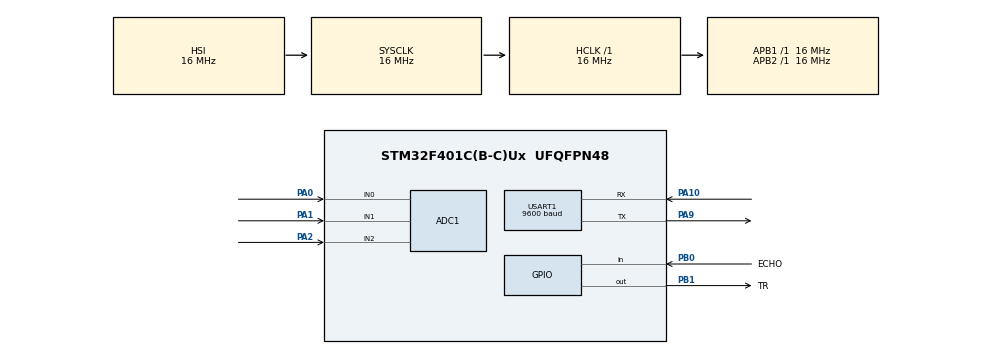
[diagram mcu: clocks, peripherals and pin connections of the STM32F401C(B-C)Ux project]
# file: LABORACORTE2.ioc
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ADC1.Channel-0\#ChannelRegularConversion=ADC_CHANNEL_0
ADC1.Channel-1\#ChannelRegularConversion=ADC_CHANNEL_1
ADC1.Channel-2\#ChannelRegularConversion=ADC_CHANNEL_2
ADC1.NbrOfConversion=3
ADC1.NbrOfConversionFlag=1
ADC1.Rank-0\#ChannelRegularConversion=1
ADC1.Rank-1\#ChannelRegularConversion=2
ADC1.Rank-2\#ChannelRegularConversion=3
ADC1.SamplingTime-0\#ChannelRegularConversion=ADC_SAMPLETIME_84CYCLES
ADC1.SamplingTime-1\#ChannelRegularConversion=ADC_SAMPLETIME_84CYCLES
ADC1.SamplingTime-2\#ChannelRegularConversion=ADC_SAMPLETIME_84CYCLES
ADC1.master=1
Mcu.Family=STM32F4
Mcu.Name=STM32F401C(B-C)Ux
Mcu.Package=UFQFPN48
NVIC.PriorityGroup=NVIC_PRIORITYGROUP_4
PA0-WKUP.Signal=ADCx_IN0
PA1.Signal=ADCx_IN1
PA10.Mode=Asynchronous
PA10.Signal=USART1_RX
PA2.Signal=ADCx_IN2
PA9.Mode=Asynchronous
PA9.Signal=USART1_TX
PB0.GPIO_Label=ECHO
PB0.Signal=GPIO_Input
PB1.GPIO_Label=TR
PB1.Signal=GPIO_Output
ProjectManager.HeapSize=0x200
ProjectManager.StackSize=0x400
ProjectManager.TargetToolchain=CMake
RCC.AHBFreq_Value=16000000
RCC.APB1Freq_Value=16000000
RCC.APB2Freq_Value=16000000
RCC.CortexFreq_Value=16000000
RCC.HSE_VALUE=25000000
RCC.HSI_VALUE=16000000
RCC.LSE_VALUE=32768
RCC.SYSCLKFreq_VALUE=16000000
RCC.VCOOutputFreq_Value=192000000
SH.ADCx_IN0.0=ADC1_IN0,IN0
SH.ADCx_IN1.0=ADC1_IN1,IN1
SH.ADCx_IN2.0=ADC1_IN2,IN2
USART1.BaudRate=9600
USART1.VirtualMode=VM_ASYNC
board=custom

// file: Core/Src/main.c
/* USER CODE BEGIN Header */
/**
  ******************************************************************************
  * @file           : main.c
  * @brief          : Main program body
  ******************************************************************************
  * @attention
  *
  * Copyright (c) 2026 STMicroelectronics.
  * All rights reserved.
  *
  * This software is licensed under terms that can be found in the LICENSE file
  * in the root directory of this software component.
  * If no LICENSE file comes with this software, it is provided AS-IS.
  *
  ******************************************************************************
  */
/* USER CODE END Header */
#include "main.h"

/* USER CODE BEGIN Includes */
#include "stdio.h"
#include "string.h"
#include "stdlib.h"
#include "math.h"
#include "uart.h"
#include "adc_x.h"
#include "SFR04.h"
/* USER CODE END Includes */

ADC_HandleTypeDef hadc1;

UART_HandleTypeDef huart1;

/* USER CODE BEGIN PV */
uint16_t valoradc;
char buffer[100];
float voltaje;
float bateria;
float distancia;

/* USER CODE END PV */

void SystemClock_Config(void);
static void MX_GPIO_Init(void);
static void MX_ADC1_Init(void);
static void MX_USART1_UART_Init(void);

int main(void)
{

  /* MCU Configuration--------------------------------------------------------*/

  /* Reset of all peripherals, Initializes the Flash interface and the Systick. */
  HAL_Init();

  /* Configure the system clock */
  SystemClock_Config();

  /* Initialize all configured peripherals */
  MX_GPIO_Init();
  MX_ADC1_Init();
  MX_USART1_UART_Init();

  /* Infinite loop */
  while (1)
  {
    ADC_Read_All(&hadc1, adc1_canales, adc1_codigo);
    voltaje = (float)adc1_codigo[0] * 3.3 / 4095.0;
    sprintf(buffer, "voltaje pot= %.2f V\r\n", voltaje);
    uartx_write_text(&huart1, buffer);
    sprintf(buffer, ">voltaje POT: %.2f \n", voltaje);
    uartx_write_text(&huart1, buffer);
    bateria = (float)adc1_codigo[1] * 3.3 / 4095.0;
    bateria = bateria * 4.9;
    sprintf(buffer, "fuente = %.2f V\r\n", bateria);
    uartx_write_text(&huart1, buffer);
    sprintf(buffer, ">fuente: %.2f \n", bateria);
    uartx_write_text(&huart1, buffer);
    distancia = SFR04_READ(ECHO_GPIO_Port, ECHO_Pin, 60);
    sprintf(buffer, "distancia= %.2f cm\r\n", distancia);
    uartx_write_text(&huart1, buffer);
    sprintf(buffer, ">distancia: %.2f \n", distancia);
    uartx_write_text(&huart1, buffer);
    HAL_Delay(500);
  }
}

void SystemClock_Config(void)
{
  RCC_OscInitTypeDef RCC_OscInitStruct = {0};
  RCC_ClkInitTypeDef RCC_ClkInitStruct = {0};

  /** Configure the main internal regulator output voltage
  */
  __HAL_RCC_PWR_CLK_ENABLE();
  __HAL_PWR_VOLTAGESCALING_CONFIG(PWR_REGULATOR_VOLTAGE_SCALE2);

  /** Initializes the RCC Oscillators according to the specified parameters
  * in the RCC_OscInitTypeDef structure.
  */
  RCC_OscInitStruct.OscillatorType = RCC_OSCILLATORTYPE_HSI;
  RCC_OscInitStruct.HSIState = RCC_HSI_ON;
  RCC_OscInitStruct.HSICalibrationValue = RCC_HSICALIBRATION_DEFAULT;
  RCC_OscInitStruct.PLL.PLLState = RCC_PLL_NONE;
  if (HAL_RCC_OscConfig(&RCC_OscInitStruct) != HAL_OK)
  {
    Error_Handler();
  }

  /** Initializes the CPU, AHB and APB buses clocks
  */
  RCC_ClkInitStruct.ClockType = RCC_CLOCKTYPE_HCLK|RCC_CLOCKTYPE_SYSCLK
                              |RCC_CLOCKTYPE_PCLK1|RCC_CLOCKTYPE_PCLK2;
  RCC_ClkInitStruct.SYSCLKSource = RCC_SYSCLKSOURCE_HSI;
  RCC_ClkInitStruct.AHBCLKDivider = RCC_SYSCLK_DIV1;
  RCC_ClkInitStruct.APB1CLKDivider = RCC_HCLK_DIV1;
  RCC_ClkInitStruct.APB2CLKDivider = RCC_HCLK_DIV1;

  if (HAL_RCC_ClockConfig(&RCC_ClkInitStruct, FLASH_LATENCY_0) != HAL_OK)
  {
    Error_Handler();
  }
}

static void MX_ADC1_Init(void)
{

  ADC_ChannelConfTypeDef sConfig = {0};

  /** Configure the global features of the ADC (Clock, Resolution, Data Alignment and number of conversion)
  */
  hadc1.Instance = ADC1;
  hadc1.Init.ClockPrescaler = ADC_CLOCK_SYNC_PCLK_DIV2;
  hadc1.Init.Resolution = ADC_RESOLUTION_12B;
  hadc1.Init.ScanConvMode = ENABLE;
  hadc1.Init.ContinuousConvMode = DISABLE;
  hadc1.Init.DiscontinuousConvMode = DISABLE;
  hadc1.Init.ExternalTrigConvEdge = ADC_EXTERNALTRIGCONVEDGE_NONE;
  hadc1.Init.ExternalTrigConv = ADC_SOFTWARE_START;
  hadc1.Init.DataAlign = ADC_DATAALIGN_RIGHT;
  hadc1.Init.NbrOfConversion = 3;
  hadc1.Init.DMAContinuousRequests = DISABLE;
  hadc1.Init.EOCSelection = ADC_EOC_SINGLE_CONV;
  if (HAL_ADC_Init(&hadc1) != HAL_OK)
  {
    Error_Handler();
  }

  /** Configure for the selected ADC regular channel its corresponding rank in the sequencer and its sample time.
  */
  sConfig.Channel = ADC_CHANNEL_0;
  sConfig.Rank = 1;
  sConfig.SamplingTime = ADC_SAMPLETIME_84CYCLES;
  if (HAL_ADC_ConfigChannel(&hadc1, &sConfig) != HAL_OK)
  {
    Error_Handler();
  }

  /** Configure for the selected ADC regular channel its corresponding rank in the sequencer and its sample time.
  */
  sConfig.Channel = ADC_CHANNEL_1;
  sConfig.Rank = 2;
  if (HAL_ADC_ConfigChannel(&hadc1, &sConfig) != HAL_OK)
  {
    Error_Handler();
  }

  /** Configure for the selected ADC regular channel its corresponding rank in the sequencer and its sample time.
  */
  sConfig.Channel = ADC_CHANNEL_2;
  sConfig.Rank = 3;
  if (HAL_ADC_ConfigChannel(&hadc1, &sConfig) != HAL_OK)
  {
    Error_Handler();
  }

}

static void MX_USART1_UART_Init(void)
{

  huart1.Instance = USART1;
  huart1.Init.BaudRate = 9600;
  huart1.Init.WordLength = UART_WORDLENGTH_8B;
  huart1.Init.StopBits = UART_STOPBITS_1;
  huart1.Init.Parity = UART_PARITY_NONE;
  huart1.Init.Mode = UART_MODE_TX_RX;
  huart1.Init.HwFlowCtl = UART_HWCONTROL_NONE;
  huart1.Init.OverSampling = UART_OVERSAMPLING_16;
  if (HAL_UART_Init(&huart1) != HAL_OK)
  {
    Error_Handler();
  }

}

static void MX_GPIO_Init(void)
{
  GPIO_InitTypeDef GPIO_InitStruct = {0};

  /* GPIO Ports Clock Enable */
  __HAL_RCC_GPIOA_CLK_ENABLE();
  __HAL_RCC_GPIOB_CLK_ENABLE();

  /*Configure GPIO pin Output Level */
  HAL_GPIO_WritePin(TR_GPIO_Port, TR_Pin, GPIO_PIN_RESET);

  /*Configure GPIO pin : ECHO_Pin */
  GPIO_InitStruct.Pin = ECHO_Pin;
  GPIO_InitStruct.Mode = GPIO_MODE_INPUT;
  GPIO_InitStruct.Pull = GPIO_NOPULL;
  HAL_GPIO_Init(ECHO_GPIO_Port, &GPIO_InitStruct);

  /*Configure GPIO pin : TR_Pin */
  GPIO_InitStruct.Pin = TR_Pin;
  GPIO_InitStruct.Mode = GPIO_MODE_OUTPUT_PP;
  GPIO_InitStruct.Pull = GPIO_NOPULL;
  GPIO_InitStruct.Speed = GPIO_SPEED_FREQ_LOW;
  HAL_GPIO_Init(TR_GPIO_Port, &GPIO_InitStruct);

}

void Error_Handler(void)
{
  __disable_irq();
  while (1)
  {
  }
}
